# nrf9120_modem register map
Vendor: Nordic Semiconductor; Series: nrf91; File version: 1
CPU: CM4 r0p1, little endian, MPU, FPU, 3 interrupt priority bits
Registers are 32-bit, read-write, reset 0x0 unless marked. A register's access mark holds for its fields unless they carry their own. Offsets are from the block's base; [hi:lo] are bit positions; 'fields as' and 'values as' point back to an identical list.

## RCOSC32K_NS — 32.768 kHz RC oscillator
Base 0x40012000
0x00 TASKS_CAL wo — Start calibration of LFRC or LFULP oscillator
  [0] TASKS_CAL
    1=Trigger task
0x04 TASKS_CTSTART wo — Start calibration timer
  [0] TASKS_CTSTART
    1=Trigger task
0x08 TASKS_CTSTOP wo — Stop calibration timer
  [0] TASKS_CTSTOP
    1=Trigger task
0x100 EVENTS_CTTO — Calibration timer timeout
  [0] EVENTS_CTTO
    0=NotGenerated (Event not generated); 1=Generated (Event generated)
0x104 EVENTS_DONE — Calibration of LFCLK RC oscillator complete event
  [0] EVENTS_DONE
    values as EVENTS_CTTO.EVENTS_CTTO
0x108 EVENTS_CTSTARTED — Calibration timer started
  [0] EVENTS_CTSTARTED
    values as EVENTS_CTTO.EVENTS_CTTO
0x10C EVENTS_CTSTOPPED — Calibration timer stopped
  [0] EVENTS_CTSTOPPED
    values as EVENTS_CTTO.EVENTS_CTTO
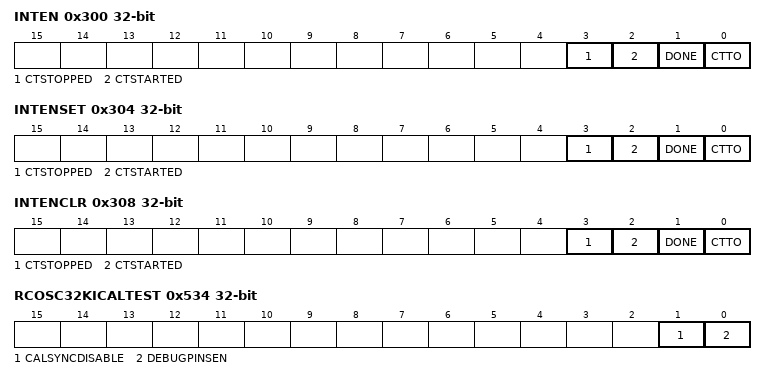
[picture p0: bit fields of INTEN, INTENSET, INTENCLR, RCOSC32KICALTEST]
0x300 INTEN — Enable or disable interrupt
  [all] fields
    0=Disabled; 1=Enabled
  [3] CTSTOPPED — Enable or disable interrupt for event CTSTOPPED
  [2] CTSTARTED — Enable or disable interrupt for event CTSTARTED
  [1] DONE — Enable or disable interrupt for event DONE
  [0] CTTO — Enable or disable interrupt for event CTTO
0x304 INTENSET — Enable interrupt
  [all] fields
    on read: 0=Disabled (Read: Disabled); 1=Enabled (Read: Enabled) | on write: 1=Set (Enable)
  [3] CTSTOPPED — Write '1' to enable interrupt for event CTSTOPPED
  [2] CTSTARTED — Write '1' to enable interrupt for event CTSTARTED
  [1] DONE — Write '1' to enable interrupt for event DONE
  [0] CTTO — Write '1' to enable interrupt for event CTTO
0x308 INTENCLR — Disable interrupt
  [all] fields
    on read: 0=Disabled (Read: Disabled); 1=Enabled (Read: Enabled) | on write: 1=Clear (Disable)
  [3] CTSTOPPED — Write '1' to disable interrupt for event CTSTOPPED
  [2] CTSTARTED — Write '1' to disable interrupt for event CTSTARTED
  [1] DONE — Write '1' to disable interrupt for event DONE
  [0] CTTO — Write '1' to disable interrupt for event CTTO
0x420 RCOSC32KIFINE ro — Fine calibration read value for 32.768 kHz RC oscillator
  [9:0] RCOSC32KIFINE
0x424 RCOSC32KICOARSE ro — Coarse calibration read value for 32.768 kHz RC oscillator
  [5:0] RCOSC32KICOARSE
0x534 RCOSC32KICALTEST — 32.768 kHz RC oscillator calibration debug register NOTE: This register should not be written to while the RCOSC source is running.
  [1] CALSYNCDISABLE — Disable calSync auto-calibration
    1=Disabled (calSync auto-calibration disabled); 0=Enabled (calSync auto-calibration enabled)
  [0] DEBUGPINSEN — Enable debug pins: calSync on P0.8 (input); ck32Ki on P0.13 (output); rcosc32KiCalib on P0.19 (output)
    0=Disabled (Pins in normal operation); 1=Enabled (Pins mapped for debug)
0x538 CTIV — Calibration timer interval NOTE: This register should not be written to while the RCOSC source is running.
  [6:0] CTIV — Calibration timer interval in multiple of 0.25 seconds. Range: 0.25 seconds to 31.75 seconds.
0x53C RCOSC32KICALLENGTH reset 0x2 — 32kHz RC oscillator calibration length This value is read from FICR
  [2:0] RCOSC32KICALLENGTH — 32kHz RC oscillator calibration length in number of cycles
    0=N64 (64 cycles); 1=N128 (128 cycles); 2=N256 (256 cycles); 3=N512 (512 cycles)
0x540 RCOSC32KICOARSEIN — RCOSC coarse calibration input This value is read from FICR
  [5:0] RCOSC32KICOARSEIN — RCOSC coarse calibration input
0x54C RCOSC32KICIRC reset 0x1 — Rotating current source for for 32.768 kHz RC oscillator
  [0] RCS — Enable or disable use of external rotating current source for 32.768 kHz RC oscillator
    0=Disabled; 1=Enabled
0x584 ATECLOCK — Analog test bus control for clock modules
  [0] RCOSC32K — Connect or disconnect 32.768 kHz RC oscillator to analog test bus
    0=Disconnected; 1=Connected (Connect internal regulator output to ATB0)
0x5B4 LFRCMODE — LFRC mode configuration
  [0] MODE — Set LFRC mode
    0=Normal mode; 1=ULP (Ultra-low power mode (ULP))
0x5B8 LFULP32KICOARSEIN — LFULP coarse calibration input This value is read from FICR
  [5:0] LFULP32KICOARSE — LFULP coarse calibration input
0x5BC LFULP32KICALLENGTH — 32kHz LFULP RC oscillator calibration length This value is read from FICR
  [2:0] LFULP32KICALLENGTH — 32kHz ULP RC oscillator calibration length in number of cycles
    values as RCOSC32KICALLENGTH.RCOSC32KICALLENGTH
0xBFC DISBALERCOSC32KIPOWERUPCONTROL — Backdoor for disabling Rcosc32KiPowerUpControl module in Rcosc32KiGenerator.
  [0] Disable — Disable Rcosc32KiPowerUpControl.
    0=Enabled (Rcosc32KiPowerUpControl is enabled.); 1=Disabled (Rcosc32KiPowerUpControl is disabled.)
